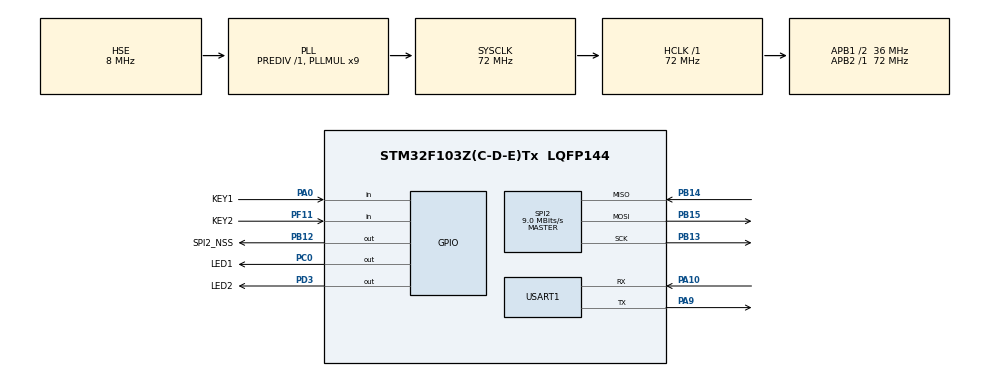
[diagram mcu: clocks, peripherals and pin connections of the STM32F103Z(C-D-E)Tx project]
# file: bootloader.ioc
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Dma.Request0=USART1_RX
Dma.Request1=USART1_TX
Dma.USART1_RX.0.Direction=DMA_PERIPH_TO_MEMORY
Dma.USART1_RX.0.Instance=DMA1_Channel5
Dma.USART1_RX.0.MemDataAlignment=DMA_MDATAALIGN_BYTE
Dma.USART1_RX.0.MemInc=DMA_MINC_ENABLE
Dma.USART1_RX.0.Mode=DMA_NORMAL
Dma.USART1_RX.0.PeriphDataAlignment=DMA_PDATAALIGN_BYTE
Dma.USART1_RX.0.PeriphInc=DMA_PINC_DISABLE
Dma.USART1_RX.0.Priority=DMA_PRIORITY_LOW
Dma.USART1_TX.1.Direction=DMA_MEMORY_TO_PERIPH
Dma.USART1_TX.1.Instance=DMA1_Channel4
Dma.USART1_TX.1.MemDataAlignment=DMA_MDATAALIGN_BYTE
Dma.USART1_TX.1.MemInc=DMA_MINC_ENABLE
Dma.USART1_TX.1.Mode=DMA_NORMAL
Dma.USART1_TX.1.PeriphDataAlignment=DMA_PDATAALIGN_BYTE
Dma.USART1_TX.1.PeriphInc=DMA_PINC_DISABLE
Dma.USART1_TX.1.Priority=DMA_PRIORITY_LOW
IWDG.Prescaler=IWDG_PRESCALER_256
Mcu.Family=STM32F1
Mcu.Name=STM32F103Z(C-D-E)Tx
Mcu.Package=LQFP144
NVIC.DMA1_Channel4_IRQn=true\:0\:0\:false\:false\:true\:false\:true\:true
NVIC.DMA1_Channel5_IRQn=true\:0\:0\:false\:false\:true\:false\:true\:true
NVIC.PriorityGroup=NVIC_PRIORITYGROUP_4
NVIC.USART1_IRQn=true\:0\:0\:false\:false\:true\:true\:true\:true
OSC_IN.Mode=HSE-External-Oscillator
OSC_IN.Signal=RCC_OSC_IN
OSC_OUT.Mode=HSE-External-Oscillator
OSC_OUT.Signal=RCC_OSC_OUT
PA0-WKUP.GPIO_Label=KEY1
PA0-WKUP.GPIO_PuPd=GPIO_PULLDOWN
PA0-WKUP.Signal=GPIO_Input
PA10.Mode=Asynchronous
PA10.Signal=USART1_RX
PA13.Mode=Serial_Wire
PA13.Signal=SYS_JTMS-SWDIO
PA14.Mode=Serial_Wire
PA14.Signal=SYS_JTCK-SWCLK
PA9.Mode=Asynchronous
PA9.Signal=USART1_TX
PB12.GPIO_Label=SPI2_NSS
PB12.Signal=GPIO_Output
PB13.Mode=Full_Duplex_Master
PB13.Signal=SPI2_SCK
PB14.Mode=Full_Duplex_Master
PB14.Signal=SPI2_MISO
PB15.Mode=Full_Duplex_Master
PB15.Signal=SPI2_MOSI
PC0.GPIO_Label=LED1
PC0.Signal=GPIO_Output
PD3.GPIO_Label=LED2
PD3.Signal=GPIO_Output
PF11.GPIO_Label=KEY2
PF11.GPIO_PuPd=GPIO_PULLDOWN
PF11.Signal=GPIO_Input
ProjectManager.HeapSize=0x200
ProjectManager.StackSize=0x400
ProjectManager.TargetToolchain=STM32CubeIDE
RCC.AHBFreq_Value=72000000
RCC.APB1CLKDivider=RCC_HCLK_DIV2
RCC.APB1Freq_Value=36000000
RCC.APB1TimFreq_Value=72000000
RCC.APB2Freq_Value=72000000
RCC.APB2TimFreq_Value=72000000
RCC.HCLKFreq_Value=72000000
RCC.PLLMUL=RCC_PLL_MUL9
RCC.PLLSourceVirtual=RCC_PLLSOURCE_HSE
RCC.SYSCLKFreq_VALUE=72000000
RCC.SYSCLKSource=RCC_SYSCLKSOURCE_PLLCLK
RCC.USBFreq_Value=72000000
SPI2.BaudRatePrescaler=SPI_BAUDRATEPRESCALER_4
SPI2.CLKPhase=SPI_PHASE_1EDGE
SPI2.CLKPolarity=SPI_POLARITY_LOW
SPI2.CalculateBaudRate=9.0 MBits/s
SPI2.Direction=SPI_DIRECTION_2LINES
SPI2.Mode=SPI_MODE_MASTER
SPI2.VirtualType=VM_MASTER
USART1.VirtualMode=VM_ASYNC
VP_IWDG_VS_IWDG.Mode=IWDG_Activate
board=custom

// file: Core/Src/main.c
/* USER CODE BEGIN Header */
/**
  ******************************************************************************
  * @file           : main.c
  * @brief          : Main program body
  ******************************************************************************
  * @attention
  *
  * Copyright (c) 2025 STMicroelectronics.
  * All rights reserved.
  *
  * This software is licensed under terms that can be found in the LICENSE file
  * in the root directory of this software component.
  * If no LICENSE file comes with this software, it is provided AS-IS.
  *
  ******************************************************************************
  */
/* USER CODE END Header */
#include "main.h"

IWDG_HandleTypeDef hiwdg;

SPI_HandleTypeDef hspi2;

UART_HandleTypeDef huart1;
DMA_HandleTypeDef hdma_usart1_rx;
DMA_HandleTypeDef hdma_usart1_tx;

void SystemClock_Config(void);
static void MX_GPIO_Init(void);
static void MX_DMA_Init(void);
static void MX_USART1_UART_Init(void);
static void MX_SPI2_Init(void);
static void MX_IWDG_Init(void);

int main(void)
{

  /* MCU Configuration--------------------------------------------------------*/

  /* Reset of all peripherals, Initializes the Flash interface and the Systick. */
  HAL_Init();

  /* Configure the system clock */
  SystemClock_Config();

  /* Initialize all configured peripherals */
  MX_GPIO_Init();
  MX_DMA_Init();
  MX_USART1_UART_Init();
  MX_SPI2_Init();
  MX_IWDG_Init();
  /* USER CODE BEGIN 2 */
  uint16_t ID = w25q128_read_id();
  uint32_t I2D = flash_read_ID();
  printf("%d\r\n",ID);
  printf("%ld\r\n",I2D);
  /* USER CODE END 2 */

  /* Infinite loop */
  while (1)
  {

    /* USER CODE BEGIN 3 */
	if(Rx1Sign)
	{

	  Rx1Sign = 0;
	  if(Rx1_Count > 6)
		  BootLoad();
	}
	HAL_GPIO_TogglePin(LED1_GPIO_Port, LED1_Pin);
	HAL_Delay(100);
	HAL_IWDG_Refresh(&hiwdg);
  }
  /* USER CODE END 3 */
}

void SystemClock_Config(void)
{
  RCC_OscInitTypeDef RCC_OscInitStruct = {0};
  RCC_ClkInitTypeDef RCC_ClkInitStruct = {0};

  /** Initializes the RCC Oscillators according to the specified parameters
  * in the RCC_OscInitTypeDef structure.
  */
  RCC_OscInitStruct.OscillatorType = RCC_OSCILLATORTYPE_LSI|RCC_OSCILLATORTYPE_HSE;
  RCC_OscInitStruct.HSEState = RCC_HSE_ON;
  RCC_OscInitStruct.HSEPredivValue = RCC_HSE_PREDIV_DIV1;
  RCC_OscInitStruct.HSIState = RCC_HSI_ON;
  RCC_OscInitStruct.LSIState = RCC_LSI_ON;
  RCC_OscInitStruct.PLL.PLLState = RCC_PLL_ON;
  RCC_OscInitStruct.PLL.PLLSource = RCC_PLLSOURCE_HSE;
  RCC_OscInitStruct.PLL.PLLMUL = RCC_PLL_MUL9;
  if (HAL_RCC_OscConfig(&RCC_OscInitStruct) != HAL_OK)
  {
    Error_Handler();
  }

  /** Initializes the CPU, AHB and APB buses clocks
  */
  RCC_ClkInitStruct.ClockType = RCC_CLOCKTYPE_HCLK|RCC_CLOCKTYPE_SYSCLK
                              |RCC_CLOCKTYPE_PCLK1|RCC_CLOCKTYPE_PCLK2;
  RCC_ClkInitStruct.SYSCLKSource = RCC_SYSCLKSOURCE_PLLCLK;
  RCC_ClkInitStruct.AHBCLKDivider = RCC_SYSCLK_DIV1;
  RCC_ClkInitStruct.APB1CLKDivider = RCC_HCLK_DIV2;
  RCC_ClkInitStruct.APB2CLKDivider = RCC_HCLK_DIV1;

  if (HAL_RCC_ClockConfig(&RCC_ClkInitStruct, FLASH_LATENCY_2) != HAL_OK)
  {
    Error_Handler();
  }
}

static void MX_IWDG_Init(void)
{

  hiwdg.Instance = IWDG;
  hiwdg.Init.Prescaler = IWDG_PRESCALER_256;
  hiwdg.Init.Reload = 4095;
  if (HAL_IWDG_Init(&hiwdg) != HAL_OK)
  {
    Error_Handler();
  }

}

static void MX_SPI2_Init(void)
{

  /* SPI2 parameter configuration*/
  hspi2.Instance = SPI2;
  hspi2.Init.Mode = SPI_MODE_MASTER;
  hspi2.Init.Direction = SPI_DIRECTION_2LINES;
  hspi2.Init.DataSize = SPI_DATASIZE_8BIT;
  hspi2.Init.CLKPolarity = SPI_POLARITY_LOW;
  hspi2.Init.CLKPhase = SPI_PHASE_1EDGE;
  hspi2.Init.NSS = SPI_NSS_SOFT;
  hspi2.Init.BaudRatePrescaler = SPI_BAUDRATEPRESCALER_4;
  hspi2.Init.FirstBit = SPI_FIRSTBIT_MSB;
  hspi2.Init.TIMode = SPI_TIMODE_DISABLE;
  hspi2.Init.CRCCalculation = SPI_CRCCALCULATION_DISABLE;
  hspi2.Init.CRCPolynomial = 10;
  if (HAL_SPI_Init(&hspi2) != HAL_OK)
  {
    Error_Handler();
  }

}

static void MX_USART1_UART_Init(void)
{

  huart1.Instance = USART1;
  huart1.Init.BaudRate = 115200;
  huart1.Init.WordLength = UART_WORDLENGTH_8B;
  huart1.Init.StopBits = UART_STOPBITS_1;
  huart1.Init.Parity = UART_PARITY_NONE;
  huart1.Init.Mode = UART_MODE_TX_RX;
  huart1.Init.HwFlowCtl = UART_HWCONTROL_NONE;
  huart1.Init.OverSampling = UART_OVERSAMPLING_16;
  if (HAL_UART_Init(&huart1) != HAL_OK)
  {
    Error_Handler();
  }
  /* USER CODE BEGIN USART1_Init 2 */
  __HAL_UART_ENABLE_IT(&huart1,UART_IT_IDLE);
  HAL_UART_Receive_DMA(&huart1,buffer_RX1,RX1_Size);
  /* USER CODE END USART1_Init 2 */

}

static void MX_DMA_Init(void)
{

  /* DMA controller clock enable */
  __HAL_RCC_DMA1_CLK_ENABLE();

  /* DMA interrupt init */
  /* DMA1_Channel4_IRQn interrupt configuration */
  HAL_NVIC_SetPriority(DMA1_Channel4_IRQn, 0, 0);
  HAL_NVIC_EnableIRQ(DMA1_Channel4_IRQn);
  /* DMA1_Channel5_IRQn interrupt configuration */
  HAL_NVIC_SetPriority(DMA1_Channel5_IRQn, 0, 0);
  HAL_NVIC_EnableIRQ(DMA1_Channel5_IRQn);

}

static void MX_GPIO_Init(void)
{
  GPIO_InitTypeDef GPIO_InitStruct = {0};

  /* GPIO Ports Clock Enable */
  __HAL_RCC_GPIOC_CLK_ENABLE();
  __HAL_RCC_GPIOA_CLK_ENABLE();
  __HAL_RCC_GPIOF_CLK_ENABLE();
  __HAL_RCC_GPIOB_CLK_ENABLE();
  __HAL_RCC_GPIOD_CLK_ENABLE();

  /*Configure GPIO pin Output Level */
  HAL_GPIO_WritePin(LED1_GPIO_Port, LED1_Pin, GPIO_PIN_RESET);

  /*Configure GPIO pin Output Level */
  HAL_GPIO_WritePin(SPI2_NSS_GPIO_Port, SPI2_NSS_Pin, GPIO_PIN_RESET);

  /*Configure GPIO pin Output Level */
  HAL_GPIO_WritePin(LED2_GPIO_Port, LED2_Pin, GPIO_PIN_RESET);

  /*Configure GPIO pin : LED1_Pin */
  GPIO_InitStruct.Pin = LED1_Pin;
  GPIO_InitStruct.Mode = GPIO_MODE_OUTPUT_PP;
  GPIO_InitStruct.Pull = GPIO_NOPULL;
  GPIO_InitStruct.Speed = GPIO_SPEED_FREQ_LOW;
  HAL_GPIO_Init(LED1_GPIO_Port, &GPIO_InitStruct);

  /*Configure GPIO pin : KEY1_Pin */
  GPIO_InitStruct.Pin = KEY1_Pin;
  GPIO_InitStruct.Mode = GPIO_MODE_INPUT;
  GPIO_InitStruct.Pull = GPIO_PULLDOWN;
  HAL_GPIO_Init(KEY1_GPIO_Port, &GPIO_InitStruct);

  /*Configure GPIO pin : KEY2_Pin */
  GPIO_InitStruct.Pin = KEY2_Pin;
  GPIO_InitStruct.Mode = GPIO_MODE_INPUT;
  GPIO_InitStruct.Pull = GPIO_PULLDOWN;
  HAL_GPIO_Init(KEY2_GPIO_Port, &GPIO_InitStruct);

  /*Configure GPIO pin : SPI2_NSS_Pin */
  GPIO_InitStruct.Pin = SPI2_NSS_Pin;
  GPIO_InitStruct.Mode = GPIO_MODE_OUTPUT_PP;
  GPIO_InitStruct.Pull = GPIO_NOPULL;
  GPIO_InitStruct.Speed = GPIO_SPEED_FREQ_LOW;
  HAL_GPIO_Init(SPI2_NSS_GPIO_Port, &GPIO_InitStruct);

  /*Configure GPIO pin : LED2_Pin */
  GPIO_InitStruct.Pin = LED2_Pin;
  GPIO_InitStruct.Mode = GPIO_MODE_OUTPUT_PP;
  GPIO_InitStruct.Pull = GPIO_NOPULL;
  GPIO_InitStruct.Speed = GPIO_SPEED_FREQ_LOW;
  HAL_GPIO_Init(LED2_GPIO_Port, &GPIO_InitStruct);

}

void Error_Handler(void)
{
  __disable_irq();
  while (1)
  {
  }
}
